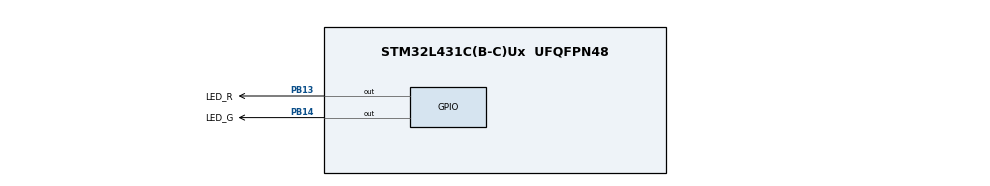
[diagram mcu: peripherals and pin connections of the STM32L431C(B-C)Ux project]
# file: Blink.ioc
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Mcu.Family=STM32L4
Mcu.Name=STM32L431C(B-C)Ux
Mcu.Package=UFQFPN48
NVIC.PriorityGroup=NVIC_PRIORITYGROUP_4
PB13.GPIO_Label=LED_R
PB13.Signal=GPIO_Output
PB14.GPIO_Label=LED_G
PB14.Signal=GPIO_Output
ProjectManager.HeapSize=0x200
ProjectManager.StackSize=0x400
ProjectManager.TargetToolchain=STM32CubeIDE
RCC.HSE_VALUE=8000000
RCC.HSI48_VALUE=48000000
RCC.HSI_VALUE=16000000
RCC.LSE_VALUE=32768
RCC.MSI_VALUE=4000000
RCC.VCOOutputFreq_Value=32000000
board=custom

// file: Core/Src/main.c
/* USER CODE BEGIN Header */
/**
  ******************************************************************************
  * @file           : main.c
  * @brief          : Main program body
  ******************************************************************************
  * @attention
  *
  * Copyright (c) 2025 STMicroelectronics.
  * All rights reserved.
  *
  * This software is licensed under terms that can be found in the LICENSE file
  * in the root directory of this software component.
  * If no LICENSE file comes with this software, it is provided AS-IS.
  *
  ******************************************************************************
  */
/* USER CODE END Header */
#include "main.h"

/* USER CODE BEGIN PV */
int count = 0;

HAL_StatusTypeDef  status;

/* USER CODE END PV */

void SystemClock_Config(void);
static void MX_GPIO_Init(void);

/* USER CODE BEGIN 0 */
/*void HAL_TIM_PeriodElapsedCallback(TIM_HandleTypeDef *htim){
	HAL_GPIO_TogglePin(LED_R_GPIO_Port, LED_R_Pin);
			  HAL_GPIO_TogglePin(LED_G_GPIO_Port, LED_G_Pin);
			  ++count;
}
*/
/* USER CODE END 0 */

int main(void)
{

  /* MCU Configuration--------------------------------------------------------*/

  /* Reset of all peripherals, Initializes the Flash interface and the Systick. */
  HAL_Init();

  /* USER CODE BEGIN Init */
//SCB->VTOR = FLASH_BASE | 0x00000000U;
  /* USER CODE END Init */

  /* Configure the system clock */
  SystemClock_Config();

  /* Initialize all configured peripherals */
  MX_GPIO_Init();
  /* USER CODE BEGIN 2 */
  //HAL_TIM_Base_Start_IT(&htim1);

  HAL_ResumeTick();
  HAL_GPIO_WritePin(LED_R_GPIO_Port, LED_R_Pin,1);

  /* USER CODE END 2 */

  /* Infinite loop */
  while (1)
  {

    /* USER CODE BEGIN 3 */
	  HAL_GPIO_TogglePin(LED_R_GPIO_Port, LED_R_Pin);
	  		  HAL_GPIO_TogglePin(LED_G_GPIO_Port, LED_G_Pin);
	  		  ++count;
	  		  HAL_Delay(100);

  }

  /* USER CODE END 3 */
}

void SystemClock_Config(void)
{
  RCC_OscInitTypeDef RCC_OscInitStruct = {0};
  RCC_ClkInitTypeDef RCC_ClkInitStruct = {0};

  /** Configure the main internal regulator output voltage
  */
  if (HAL_PWREx_ControlVoltageScaling(PWR_REGULATOR_VOLTAGE_SCALE1) != HAL_OK)
  {
    Error_Handler();
  }

  /** Initializes the RCC Oscillators according to the specified parameters
  * in the RCC_OscInitTypeDef structure.
  */
  RCC_OscInitStruct.OscillatorType = RCC_OSCILLATORTYPE_MSI;
  RCC_OscInitStruct.MSIState = RCC_MSI_ON;
  RCC_OscInitStruct.MSICalibrationValue = 0;
  RCC_OscInitStruct.MSIClockRange = RCC_MSIRANGE_6;
  RCC_OscInitStruct.PLL.PLLState = RCC_PLL_NONE;
  if (HAL_RCC_OscConfig(&RCC_OscInitStruct) != HAL_OK)
  {
    Error_Handler();
  }

  /** Initializes the CPU, AHB and APB buses clocks
  */
  RCC_ClkInitStruct.ClockType = RCC_CLOCKTYPE_HCLK|RCC_CLOCKTYPE_SYSCLK
                              |RCC_CLOCKTYPE_PCLK1|RCC_CLOCKTYPE_PCLK2;
  RCC_ClkInitStruct.SYSCLKSource = RCC_SYSCLKSOURCE_MSI;
  RCC_ClkInitStruct.AHBCLKDivider = RCC_SYSCLK_DIV1;
  RCC_ClkInitStruct.APB1CLKDivider = RCC_HCLK_DIV1;
  RCC_ClkInitStruct.APB2CLKDivider = RCC_HCLK_DIV1;

  if (HAL_RCC_ClockConfig(&RCC_ClkInitStruct, FLASH_LATENCY_0) != HAL_OK)
  {
    Error_Handler();
  }
  SCB->VTOR = FLASH_BASE | 0x00000000U;
}

static void MX_GPIO_Init(void)
{
  GPIO_InitTypeDef GPIO_InitStruct = {0};

  /* GPIO Ports Clock Enable */
  __HAL_RCC_GPIOB_CLK_ENABLE();

  /*Configure GPIO pin Output Level */
  HAL_GPIO_WritePin(GPIOB, LED_R_Pin|LED_G_Pin, GPIO_PIN_RESET);

  /*Configure GPIO pins : LED_R_Pin LED_G_Pin */
  GPIO_InitStruct.Pin = LED_R_Pin|LED_G_Pin;
  GPIO_InitStruct.Mode = GPIO_MODE_OUTPUT_PP;
  GPIO_InitStruct.Pull = GPIO_NOPULL;
  GPIO_InitStruct.Speed = GPIO_SPEED_FREQ_LOW;
  HAL_GPIO_Init(GPIOB, &GPIO_InitStruct);

}

void Error_Handler(void)
{
  __disable_irq();
  while (1)
  {
  }
}
